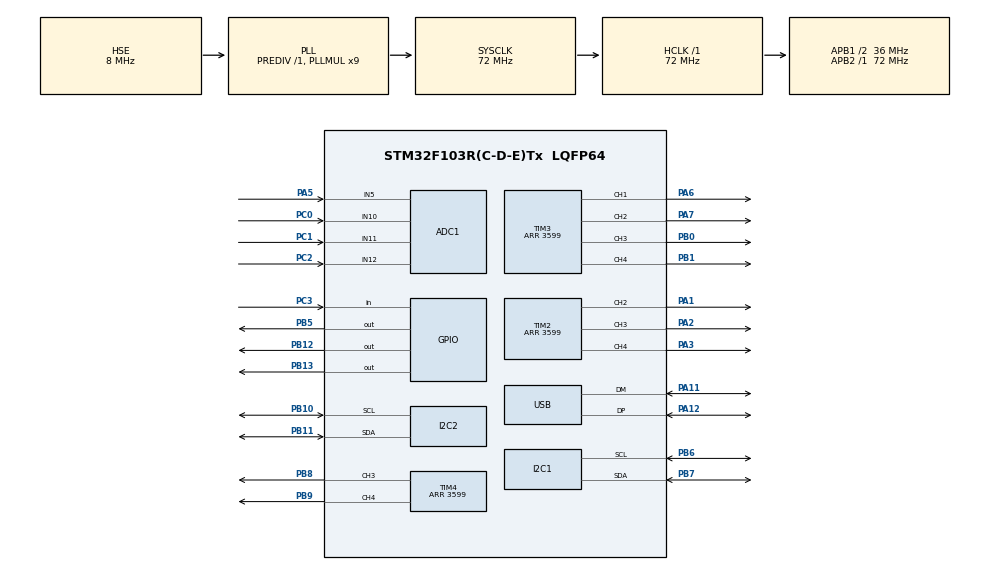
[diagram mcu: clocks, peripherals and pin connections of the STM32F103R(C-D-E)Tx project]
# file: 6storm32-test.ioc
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ADC1.Channel-0\#ChannelRegularConversion=ADC_CHANNEL_5
ADC1.Channel-1\#ChannelRegularConversion=ADC_CHANNEL_10
ADC1.Channel-2\#ChannelRegularConversion=ADC_CHANNEL_11
ADC1.Channel-3\#ChannelRegularConversion=ADC_CHANNEL_12
ADC1.ContinuousConvMode=ENABLE
ADC1.NbrOfConversion=4
ADC1.NbrOfConversionFlag=1
ADC1.Rank-0\#ChannelRegularConversion=1
ADC1.Rank-1\#ChannelRegularConversion=2
ADC1.Rank-2\#ChannelRegularConversion=3
ADC1.Rank-3\#ChannelRegularConversion=4
ADC1.SamplingTime-0\#ChannelRegularConversion=ADC_SAMPLETIME_55CYCLES_5
ADC1.SamplingTime-1\#ChannelRegularConversion=ADC_SAMPLETIME_55CYCLES_5
ADC1.SamplingTime-2\#ChannelRegularConversion=ADC_SAMPLETIME_55CYCLES_5
ADC1.SamplingTime-3\#ChannelRegularConversion=ADC_SAMPLETIME_55CYCLES_5
ADC1.master=1
Dma.ADC1.0.Direction=DMA_PERIPH_TO_MEMORY
Dma.ADC1.0.Instance=DMA1_Channel1
Dma.ADC1.0.MemDataAlignment=DMA_MDATAALIGN_HALFWORD
Dma.ADC1.0.MemInc=DMA_MINC_ENABLE
Dma.ADC1.0.Mode=DMA_CIRCULAR
Dma.ADC1.0.PeriphDataAlignment=DMA_PDATAALIGN_HALFWORD
Dma.ADC1.0.PeriphInc=DMA_PINC_DISABLE
Dma.ADC1.0.Priority=DMA_PRIORITY_LOW
Dma.Request0=ADC1
I2C2.I2C_Mode=I2C_Standard
Mcu.Family=STM32F1
Mcu.Name=STM32F103R(C-D-E)Tx
Mcu.Package=LQFP64
NVIC.DMA1_Channel1_IRQn=true\:0\:0\:false\:false\:true\:false\:true\:true
NVIC.PriorityGroup=NVIC_PRIORITYGROUP_4
NVIC.USB_LP_CAN1_RX0_IRQn=true\:0\:0\:false\:false\:true\:false\:true\:true
PA1.Signal=S_TIM2_CH2
PA11.Mode=Device
PA11.Signal=USB_DM
PA12.Mode=Device
PA12.Signal=USB_DP
PA13.Mode=Serial_Wire
PA13.Signal=SYS_JTMS-SWDIO
PA14.Mode=Serial_Wire
PA14.Signal=SYS_JTCK-SWCLK
PA2.Signal=S_TIM2_CH3
PA3.Signal=S_TIM2_CH4
PA5.Signal=ADCx_IN5
PA6.Signal=S_TIM3_CH1
PA7.Signal=S_TIM3_CH2
PB0.Signal=S_TIM3_CH3
PB1.Signal=S_TIM3_CH4
PB10.Mode=I2C
PB10.Signal=I2C2_SCL
PB11.Mode=I2C
PB11.Signal=I2C2_SDA
PB12.Signal=GPIO_Output
PB13.Signal=GPIO_Output
PB5.GPIO_ModeDefaultOutputPP=GPIO_MODE_OUTPUT_OD
PB5.GPIO_PuPd=GPIO_NOPULL
PB5.Signal=GPIO_Output
PB6.Mode=I2C
PB6.Signal=I2C1_SCL
PB7.Mode=I2C
PB7.Signal=I2C1_SDA
PB8.Signal=S_TIM4_CH3
PB9.Signal=S_TIM4_CH4
PC0.Signal=ADCx_IN10
PC1.Signal=ADCx_IN11
PC2.Signal=ADCx_IN12
PC3.GPIO_PuPd=GPIO_PULLUP
PC3.Signal=GPIO_Input
PD0-OSC_IN.Mode=HSE-External-Oscillator
PD0-OSC_IN.Signal=RCC_OSC_IN
PD1-OSC_OUT.Mode=HSE-External-Oscillator
PD1-OSC_OUT.Signal=RCC_OSC_OUT
ProjectManager.HeapSize=0x200
ProjectManager.StackSize=0x400
ProjectManager.TargetToolchain=STM32CubeIDE
RCC.ADCPresc=RCC_ADCPCLK2_DIV6
RCC.AHBFreq_Value=72000000
RCC.APB1CLKDivider=RCC_HCLK_DIV2
RCC.APB1Freq_Value=36000000
RCC.APB1TimFreq_Value=72000000
RCC.APB2Freq_Value=72000000
RCC.APB2TimFreq_Value=72000000
RCC.HCLKFreq_Value=72000000
RCC.PLLMUL=RCC_PLL_MUL9
RCC.PLLSourceVirtual=RCC_PLLSOURCE_HSE
RCC.SYSCLKFreq_VALUE=72000000
RCC.SYSCLKSource=RCC_SYSCLKSOURCE_PLLCLK
RCC.USBFreq_Value=48000000
RCC.USBPrescaler=RCC_USBCLKSOURCE_PLL_DIV1_5
SH.ADCx_IN10.0=ADC1_IN10,IN10
SH.ADCx_IN11.0=ADC1_IN11,IN11
SH.ADCx_IN12.0=ADC1_IN12,IN12
SH.ADCx_IN5.0=ADC1_IN5,IN5
SH.S_TIM2_CH2.0=TIM2_CH2,PWM Generation2 CH2
SH.S_TIM2_CH3.0=TIM2_CH3,PWM Generation3 CH3
SH.S_TIM2_CH4.0=TIM2_CH4,PWM Generation4 CH4
SH.S_TIM3_CH1.0=TIM3_CH1,PWM Generation1 CH1
SH.S_TIM3_CH2.0=TIM3_CH2,PWM Generation2 CH2
SH.S_TIM3_CH3.0=TIM3_CH3,PWM Generation3 CH3
SH.S_TIM3_CH4.0=TIM3_CH4,PWM Generation4 CH4
SH.S_TIM4_CH3.0=TIM4_CH3,PWM Generation3 CH3
SH.S_TIM4_CH4.0=TIM4_CH4,PWM Generation4 CH4
TIM2.Channel-PWM\ Generation2\ CH2=TIM_CHANNEL_2
TIM2.Channel-PWM\ Generation3\ CH3=TIM_CHANNEL_3
TIM2.Channel-PWM\ Generation4\ CH4=TIM_CHANNEL_4
TIM2.Period=3599
TIM3.Channel-PWM\ Generation1\ CH1=TIM_CHANNEL_1
TIM3.Channel-PWM\ Generation2\ CH2=TIM_CHANNEL_2
TIM3.Channel-PWM\ Generation3\ CH3=TIM_CHANNEL_3
TIM3.Channel-PWM\ Generation4\ CH4=TIM_CHANNEL_4
TIM3.Period=3599
TIM4.Channel-PWM\ Generation3\ CH3=TIM_CHANNEL_3
TIM4.Channel-PWM\ Generation4\ CH4=TIM_CHANNEL_4
TIM4.Period=3599
USB_DEVICE.CLASS_NAME_FS=CDC
USB_DEVICE.VirtualMode=Cdc
USB_DEVICE.VirtualModeFS=Cdc_FS
VP_USB_DEVICE_VS_USB_DEVICE_CDC_FS.Mode=CDC_FS
board=custom

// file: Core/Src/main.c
/* USER CODE BEGIN Header */
/**
  ******************************************************************************
  * @file           : main.c
  * @brief          : Main program body
  ******************************************************************************
  * @attention
  *
  * Copyright (c) 2026 STMicroelectronics.
  * All rights reserved.
  *
  * This software is licensed under terms that can be found in the LICENSE file
  * in the root directory of this software component.
  * If no LICENSE file comes with this software, it is provided AS-IS.
  *
  ******************************************************************************
  */
/* USER CODE END Header */
#include "main.h"
#include "usb_device.h"

/* USER CODE BEGIN Includes */
#include "gimbal_app.h"
/* USER CODE END Includes */

ADC_HandleTypeDef hadc1;
DMA_HandleTypeDef hdma_adc1;

I2C_HandleTypeDef hi2c1;
I2C_HandleTypeDef hi2c2;

TIM_HandleTypeDef htim2;
TIM_HandleTypeDef htim3;
TIM_HandleTypeDef htim4;

void SystemClock_Config(void);
static void MX_GPIO_Init(void);
static void MX_DMA_Init(void);
static void MX_ADC1_Init(void);
static void MX_I2C1_Init(void);
static void MX_I2C2_Init(void);
static void MX_TIM2_Init(void);
static void MX_TIM3_Init(void);
static void MX_TIM4_Init(void);

int main(void)
{

  /* MCU Configuration--------------------------------------------------------*/

  /* Reset of all peripherals, Initializes the Flash interface and the Systick. */
  HAL_Init();

  /* Configure the system clock */
  SystemClock_Config();

  /* Initialize all configured peripherals */
  MX_GPIO_Init();
  MX_DMA_Init();
  MX_ADC1_Init();
  MX_I2C1_Init();
  MX_I2C2_Init();
  MX_TIM2_Init();
  MX_TIM3_Init();
  MX_TIM4_Init();
  MX_USB_DEVICE_Init();
  /* USER CODE BEGIN 2 */
  HAL_Delay(100U); /* Force USB disconnect while PB5 is low. */
  Gimbal_Init();
  HAL_GPIO_WritePin(GPIOB, GPIO_PIN_5, GPIO_PIN_SET);
/* USER CODE END 2 */

  /* Infinite loop */
  while (1)
  {

    /* USER CODE BEGIN 3 */
    Gimbal_Task();
  }
  /* USER CODE END 3 */
}

void SystemClock_Config(void)
{
  RCC_OscInitTypeDef RCC_OscInitStruct = {0};
  RCC_ClkInitTypeDef RCC_ClkInitStruct = {0};
  RCC_PeriphCLKInitTypeDef PeriphClkInit = {0};

  /** Initializes the RCC Oscillators according to the specified parameters
  * in the RCC_OscInitTypeDef structure.
  */
  RCC_OscInitStruct.OscillatorType = RCC_OSCILLATORTYPE_HSE;
  RCC_OscInitStruct.HSEState = RCC_HSE_ON;
  RCC_OscInitStruct.HSEPredivValue = RCC_HSE_PREDIV_DIV1;
  RCC_OscInitStruct.HSIState = RCC_HSI_ON;
  RCC_OscInitStruct.PLL.PLLState = RCC_PLL_ON;
  RCC_OscInitStruct.PLL.PLLSource = RCC_PLLSOURCE_HSE;
  RCC_OscInitStruct.PLL.PLLMUL = RCC_PLL_MUL9;
  if (HAL_RCC_OscConfig(&RCC_OscInitStruct) != HAL_OK)
  {
    Error_Handler();
  }

  /** Initializes the CPU, AHB and APB buses clocks
  */
  RCC_ClkInitStruct.ClockType = RCC_CLOCKTYPE_HCLK|RCC_CLOCKTYPE_SYSCLK
                              |RCC_CLOCKTYPE_PCLK1|RCC_CLOCKTYPE_PCLK2;
  RCC_ClkInitStruct.SYSCLKSource = RCC_SYSCLKSOURCE_PLLCLK;
  RCC_ClkInitStruct.AHBCLKDivider = RCC_SYSCLK_DIV1;
  RCC_ClkInitStruct.APB1CLKDivider = RCC_HCLK_DIV2;
  RCC_ClkInitStruct.APB2CLKDivider = RCC_HCLK_DIV1;

  if (HAL_RCC_ClockConfig(&RCC_ClkInitStruct, FLASH_LATENCY_2) != HAL_OK)
  {
    Error_Handler();
  }
  PeriphClkInit.PeriphClockSelection = RCC_PERIPHCLK_ADC|RCC_PERIPHCLK_USB;
  PeriphClkInit.AdcClockSelection = RCC_ADCPCLK2_DIV6;
  PeriphClkInit.UsbClockSelection = RCC_USBCLKSOURCE_PLL_DIV1_5;
  if (HAL_RCCEx_PeriphCLKConfig(&PeriphClkInit) != HAL_OK)
  {
    Error_Handler();
  }
}

static void MX_ADC1_Init(void)
{

  ADC_ChannelConfTypeDef sConfig = {0};

  /** Common config
  */
  hadc1.Instance = ADC1;
  hadc1.Init.ScanConvMode = ADC_SCAN_ENABLE;
  hadc1.Init.ContinuousConvMode = ENABLE;
  hadc1.Init.DiscontinuousConvMode = DISABLE;
  hadc1.Init.ExternalTrigConv = ADC_SOFTWARE_START;
  hadc1.Init.DataAlign = ADC_DATAALIGN_RIGHT;
  hadc1.Init.NbrOfConversion = 4;
  if (HAL_ADC_Init(&hadc1) != HAL_OK)
  {
    Error_Handler();
  }

  /** Configure Regular Channel
  */
  sConfig.Channel = ADC_CHANNEL_5;
  sConfig.Rank = ADC_REGULAR_RANK_1;
  sConfig.SamplingTime = ADC_SAMPLETIME_55CYCLES_5;
  if (HAL_ADC_ConfigChannel(&hadc1, &sConfig) != HAL_OK)
  {
    Error_Handler();
  }

  /** Configure Regular Channel
  */
  sConfig.Channel = ADC_CHANNEL_10;
  sConfig.Rank = ADC_REGULAR_RANK_2;
  if (HAL_ADC_ConfigChannel(&hadc1, &sConfig) != HAL_OK)
  {
    Error_Handler();
  }

  /** Configure Regular Channel
  */
  sConfig.Channel = ADC_CHANNEL_11;
  sConfig.Rank = ADC_REGULAR_RANK_3;
  if (HAL_ADC_ConfigChannel(&hadc1, &sConfig) != HAL_OK)
  {
    Error_Handler();
  }

  /** Configure Regular Channel
  */
  sConfig.Channel = ADC_CHANNEL_12;
  sConfig.Rank = ADC_REGULAR_RANK_4;
  if (HAL_ADC_ConfigChannel(&hadc1, &sConfig) != HAL_OK)
  {
    Error_Handler();
  }

}

static void MX_I2C1_Init(void)
{

  hi2c1.Instance = I2C1;
  hi2c1.Init.ClockSpeed = 100000;
  hi2c1.Init.DutyCycle = I2C_DUTYCYCLE_2;
  hi2c1.Init.OwnAddress1 = 0;
  hi2c1.Init.AddressingMode = I2C_ADDRESSINGMODE_7BIT;
  hi2c1.Init.DualAddressMode = I2C_DUALADDRESS_DISABLE;
  hi2c1.Init.OwnAddress2 = 0;
  hi2c1.Init.GeneralCallMode = I2C_GENERALCALL_DISABLE;
  hi2c1.Init.NoStretchMode = I2C_NOSTRETCH_DISABLE;
  if (HAL_I2C_Init(&hi2c1) != HAL_OK)
  {
    Error_Handler();
  }

}

static void MX_I2C2_Init(void)
{

  hi2c2.Instance = I2C2;
  hi2c2.Init.ClockSpeed = 100000;
  hi2c2.Init.DutyCycle = I2C_DUTYCYCLE_2;
  hi2c2.Init.OwnAddress1 = 0;
  hi2c2.Init.AddressingMode = I2C_ADDRESSINGMODE_7BIT;
  hi2c2.Init.DualAddressMode = I2C_DUALADDRESS_DISABLE;
  hi2c2.Init.OwnAddress2 = 0;
  hi2c2.Init.GeneralCallMode = I2C_GENERALCALL_DISABLE;
  hi2c2.Init.NoStretchMode = I2C_NOSTRETCH_DISABLE;
  if (HAL_I2C_Init(&hi2c2) != HAL_OK)
  {
    Error_Handler();
  }

}

static void MX_TIM2_Init(void)
{

  TIM_MasterConfigTypeDef sMasterConfig = {0};
  TIM_OC_InitTypeDef sConfigOC = {0};

  htim2.Instance = TIM2;
  htim2.Init.Prescaler = 0;
  htim2.Init.CounterMode = TIM_COUNTERMODE_UP;
  htim2.Init.Period = 3599;
  htim2.Init.ClockDivision = TIM_CLOCKDIVISION_DIV1;
  htim2.Init.AutoReloadPreload = TIM_AUTORELOAD_PRELOAD_DISABLE;
  if (HAL_TIM_PWM_Init(&htim2) != HAL_OK)
  {
    Error_Handler();
  }
  sMasterConfig.MasterOutputTrigger = TIM_TRGO_RESET;
  sMasterConfig.MasterSlaveMode = TIM_MASTERSLAVEMODE_DISABLE;
  if (HAL_TIMEx_MasterConfigSynchronization(&htim2, &sMasterConfig) != HAL_OK)
  {
    Error_Handler();
  }
  sConfigOC.OCMode = TIM_OCMODE_PWM1;
  sConfigOC.Pulse = 0;
  sConfigOC.OCPolarity = TIM_OCPOLARITY_HIGH;
  sConfigOC.OCFastMode = TIM_OCFAST_DISABLE;
  if (HAL_TIM_PWM_ConfigChannel(&htim2, &sConfigOC, TIM_CHANNEL_2) != HAL_OK)
  {
    Error_Handler();
  }
  if (HAL_TIM_PWM_ConfigChannel(&htim2, &sConfigOC, TIM_CHANNEL_3) != HAL_OK)
  {
    Error_Handler();
  }
  if (HAL_TIM_PWM_ConfigChannel(&htim2, &sConfigOC, TIM_CHANNEL_4) != HAL_OK)
  {
    Error_Handler();
  }
  HAL_TIM_MspPostInit(&htim2);

}

static void MX_TIM3_Init(void)
{

  TIM_MasterConfigTypeDef sMasterConfig = {0};
  TIM_OC_InitTypeDef sConfigOC = {0};

  htim3.Instance = TIM3;
  htim3.Init.Prescaler = 0;
  htim3.Init.CounterMode = TIM_COUNTERMODE_UP;
  htim3.Init.Period = 3599;
  htim3.Init.ClockDivision = TIM_CLOCKDIVISION_DIV1;
  htim3.Init.AutoReloadPreload = TIM_AUTORELOAD_PRELOAD_DISABLE;
  if (HAL_TIM_PWM_Init(&htim3) != HAL_OK)
  {
    Error_Handler();
  }
  sMasterConfig.MasterOutputTrigger = TIM_TRGO_RESET;
  sMasterConfig.MasterSlaveMode = TIM_MASTERSLAVEMODE_DISABLE;
  if (HAL_TIMEx_MasterConfigSynchronization(&htim3, &sMasterConfig) != HAL_OK)
  {
    Error_Handler();
  }
  sConfigOC.OCMode = TIM_OCMODE_PWM1;
  sConfigOC.Pulse = 0;
  sConfigOC.OCPolarity = TIM_OCPOLARITY_HIGH;
  sConfigOC.OCFastMode = TIM_OCFAST_DISABLE;
  if (HAL_TIM_PWM_ConfigChannel(&htim3, &sConfigOC, TIM_CHANNEL_1) != HAL_OK)
  {
    Error_Handler();
  }
  if (HAL_TIM_PWM_ConfigChannel(&htim3, &sConfigOC, TIM_CHANNEL_2) != HAL_OK)
  {
    Error_Handler();
  }
  if (HAL_TIM_PWM_ConfigChannel(&htim3, &sConfigOC, TIM_CHANNEL_3) != HAL_OK)
  {
    Error_Handler();
  }
  if (HAL_TIM_PWM_ConfigChannel(&htim3, &sConfigOC, TIM_CHANNEL_4) != HAL_OK)
  {
    Error_Handler();
  }
  HAL_TIM_MspPostInit(&htim3);

}

static void MX_TIM4_Init(void)
{

  TIM_MasterConfigTypeDef sMasterConfig = {0};
  TIM_OC_InitTypeDef sConfigOC = {0};

  htim4.Instance = TIM4;
  htim4.Init.Prescaler = 0;
  htim4.Init.CounterMode = TIM_COUNTERMODE_UP;
  htim4.Init.Period = 3599;
  htim4.Init.ClockDivision = TIM_CLOCKDIVISION_DIV1;
  htim4.Init.AutoReloadPreload = TIM_AUTORELOAD_PRELOAD_DISABLE;
  if (HAL_TIM_PWM_Init(&htim4) != HAL_OK)
  {
    Error_Handler();
  }
  sMasterConfig.MasterOutputTrigger = TIM_TRGO_RESET;
  sMasterConfig.MasterSlaveMode = TIM_MASTERSLAVEMODE_DISABLE;
  if (HAL_TIMEx_MasterConfigSynchronization(&htim4, &sMasterConfig) != HAL_OK)
  {
    Error_Handler();
  }
  sConfigOC.OCMode = TIM_OCMODE_PWM1;
  sConfigOC.Pulse = 0;
  sConfigOC.OCPolarity = TIM_OCPOLARITY_HIGH;
  sConfigOC.OCFastMode = TIM_OCFAST_DISABLE;
  if (HAL_TIM_PWM_ConfigChannel(&htim4, &sConfigOC, TIM_CHANNEL_3) != HAL_OK)
  {
    Error_Handler();
  }
  if (HAL_TIM_PWM_ConfigChannel(&htim4, &sConfigOC, TIM_CHANNEL_4) != HAL_OK)
  {
    Error_Handler();
  }
  HAL_TIM_MspPostInit(&htim4);

}

static void MX_DMA_Init(void)
{

  /* DMA controller clock enable */
  __HAL_RCC_DMA1_CLK_ENABLE();

  /* DMA interrupt init */
  /* DMA1_Channel1_IRQn interrupt configuration */
  HAL_NVIC_SetPriority(DMA1_Channel1_IRQn, 0, 0);
  HAL_NVIC_EnableIRQ(DMA1_Channel1_IRQn);

}

static void MX_GPIO_Init(void)
{
  GPIO_InitTypeDef GPIO_InitStruct = {0};

  /* GPIO Ports Clock Enable */
  __HAL_RCC_GPIOD_CLK_ENABLE();
  __HAL_RCC_GPIOC_CLK_ENABLE();
  __HAL_RCC_GPIOA_CLK_ENABLE();
  __HAL_RCC_GPIOB_CLK_ENABLE();

  /*Configure GPIO pin Output Level */
  HAL_GPIO_WritePin(GPIOB, GPIO_PIN_12|GPIO_PIN_13|GPIO_PIN_5, GPIO_PIN_RESET);

  /*Configure GPIO pin : PC3 */
  GPIO_InitStruct.Pin = GPIO_PIN_3;
  GPIO_InitStruct.Mode = GPIO_MODE_INPUT;
  GPIO_InitStruct.Pull = GPIO_PULLUP;
  HAL_GPIO_Init(GPIOC, &GPIO_InitStruct);

  /*Configure GPIO pins : PB12 PB13 */
  GPIO_InitStruct.Pin = GPIO_PIN_12|GPIO_PIN_13;
  GPIO_InitStruct.Mode = GPIO_MODE_OUTPUT_PP;
  GPIO_InitStruct.Pull = GPIO_NOPULL;
  GPIO_InitStruct.Speed = GPIO_SPEED_FREQ_LOW;
  HAL_GPIO_Init(GPIOB, &GPIO_InitStruct);

  /*Configure GPIO pin : PB5 */
  GPIO_InitStruct.Pin = GPIO_PIN_5;
  GPIO_InitStruct.Mode = GPIO_MODE_OUTPUT_OD;
  GPIO_InitStruct.Pull = GPIO_NOPULL;
  GPIO_InitStruct.Speed = GPIO_SPEED_FREQ_LOW;
  HAL_GPIO_Init(GPIOB, &GPIO_InitStruct);

}

void Error_Handler(void)
{
  /* USER CODE BEGIN Error_Handler_Debug */
  Gimbal_EmergencyStop();
  __disable_irq();
  while (1) {}
  /* USER CODE END Error_Handler_Debug */
}
